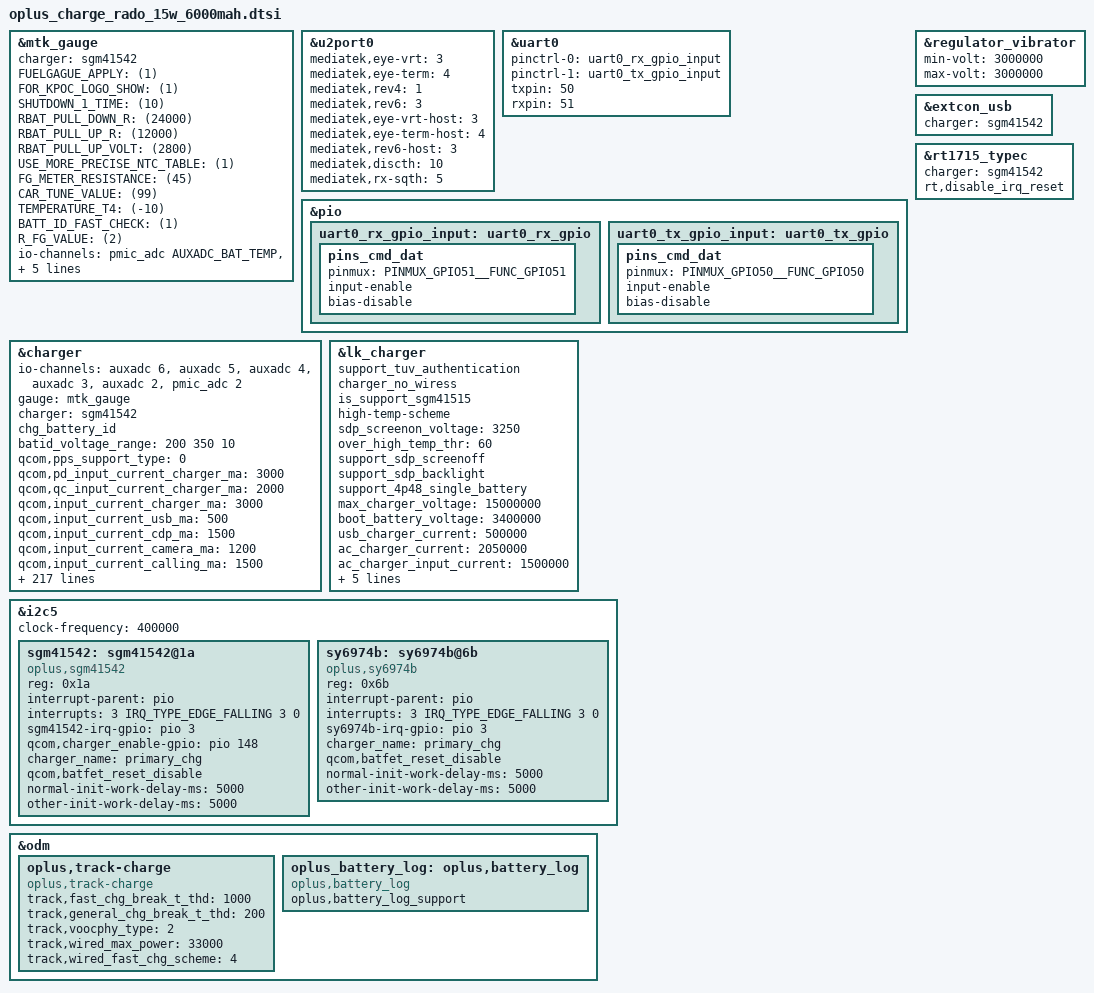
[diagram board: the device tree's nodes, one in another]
// SPDX-License-Identifier: GPL-2.0-only
/*
* Copyright (C) 2021-2020 Oplus. All rights reserved.
*/

/*
 *
 * CPU:MT6835 Barley
 * UTXD0 -->GPIO50
 * URXD0 -->GPIO51
 * I2C
 * MASTER_CHG/CCLOGIC --> I2C5
 * IRQB
 * EINT_CHG_1 (cp1 irq)                -->GPIO6
 * EINT_CHG_2 (cp2 irq)                -->GPIO18
 * CC_CNTL_INT_N(cc login irq)          --> GPIO12
 * CHG_INT(main irq)           --> GPIO3
 *
 * GPIO
 * MAIN/CCLOGIN_SCL               --> GPIO137(SCL5)
 * MAIN/CCLOGIN_SDA               --> GPIO138(SDA5)
 * USB_SWITCH_2(uart/vooc switch)      --> GPIO4
 * VBUS_SHORT(防烧口)           --> GPIO34
 * CHARGER_PUMP1_SCL               --> GPIO133(CP1_SCL3)
 * CHARGER_PUMP1_SDA               --> GPIO134(CP1_SDA3)
 * CHARGER_PUMP2_SCL               --> GPIO141(CP2_SCL7)
 * CHARGER_PUMP2_SDA               --> GPIO142(CP2_SDA7)
 * SEC_IC (加密电池GPIO for 67W)    --> GPIO44
 *
 * AP_AUXADC:
 * 0				--> FLASH_LED1_NTC
 * 1				--> NTC_USBCON_TEM (BTB VBUS旁)
 * 2				--> NTC_CHARGE (充电IC旁)
 * 3				--> USB_TEM2_ADC (BB_USB_ADC2 r/l?)
 * 4				--> USB_TEM1_ADC (BB_USB_ADC1)
 * 5				--> BAT_ID_ADC   (battery id)
 * 6				--> NTC_charging （BTB电池座子旁）
 */


#include <dt-bindings/iio/mt635x-auxadc.h>
#include <dt-bindings/pinctrl/mt6373-pinfunc.h>
#include <dt-bindings/pinctrl/mt65xx.h>
#include "oplus_chg.h"
/* charge start */

&mtk_gauge {
	status = "okay";
	charger = <&sgm41542>;
	FUELGAGUE_APPLY = <(1)>;
	FOR_KPOC_LOGO_SHOW = <(1)>;
	SHUTDOWN_1_TIME = <(10)>;
	RBAT_PULL_DOWN_R = <(24000)>;
	RBAT_PULL_UP_R = <(12000)>;
	RBAT_PULL_UP_VOLT = <(2800)>;
	USE_MORE_PRECISE_NTC_TABLE = <(1)>;
	//NTC_SERIES_R = <(5100)>;
	FG_METER_RESISTANCE = <(45)>; /* The resistance of PCB */
	CAR_TUNE_VALUE = <(99)>; /* Tune value for current measurement */
	TEMPERATURE_T4 = <(-10)>;
	BATT_ID_FAST_CHECK = <(1)>;
	R_FG_VALUE = <(2)>;/* R_sense resistance */
	io-channels = <&pmic_adc AUXADC_BAT_TEMP>,
				<&pmic_adc AUXADC_BATADC>,
				<&pmic_adc AUXADC_VBIF>,
				<&pmic_adc AUXADC_IMP>,
				<&pmic_adc AUXADC_IMIX_R>,
				<&auxadc 5>;
	io-channel-names = "pmic_battery_temp",
					"pmic_battery_voltage",
					"pmic_bif_voltage",
					"pmic_ptim_voltage",
					"pmic_ptim_r",
					 "auxadc5-batt_id_v";


    //IS_SUBBOARD_TEMP_SUPPORT = <(1)>;
	Enable_Is_Force_Full = <(1)>;
	DIM2_TABLE_DISTINGUISH = <(1)>;
	#include "mediatek/bat_setting/mt6835_rado_battery_table_15w_6000mah.dtsi"
	#include "mediatek/bat_setting/mt6835_rado_battery_prop_dim2_ext_15w_6000mah.dtsi"
};

&u2port0 {
    mediatek,eye-vrt = <3>;
    mediatek,eye-term = <4>;
    mediatek,rev4 = <1>;
    mediatek,rev6 = <3>;
    mediatek,eye-vrt-host = <3>;
    mediatek,eye-term-host = <4>;
    mediatek,rev6-host = <3>;
    mediatek,discth = <10>;
    mediatek,rx-sqth = <5>;
};

&uart0 {
	pinctrl-names = "uart0_rx_gpio", "uart0_tx_gpio";
	pinctrl-0 = <&uart0_rx_gpio_input>;
	pinctrl-1 = <&uart0_tx_gpio_input>;
	status = "okay";

	txpin = <50>;
	rxpin = <51>;
};

&pio {
	uart0_rx_gpio_input: uart0_rx_gpio {
		pins_cmd_dat {
			pinmux = <PINMUX_GPIO51__FUNC_GPIO51>;
			input-enable;
			bias-disable;
		};
	};

	uart0_tx_gpio_input: uart0_tx_gpio {
		pins_cmd_dat {
			pinmux = <PINMUX_GPIO50__FUNC_GPIO50>;
			input-enable;
			bias-disable;
		};
	};
};


&charger {
	io-channels = <&auxadc 6>,<&auxadc 5>,<&auxadc 4>,<&auxadc 3>,<&auxadc 2>,<&pmic_adc 2>;
	io-channel-names = "auxadc6_batt_btb_temp","auxadc5temp","usb_temp_v_l","usb_temp_v_r","auxadc2-chargeric_temp","pmic_vcdt_voltage";

	gauge = <&mtk_gauge>;
	charger = <&sgm41542>;

	chg_battery_id;
	batid_voltage_range = <200 350 10>;
	//for oplus chg framework:
	//qcom,pd_disable;
	qcom,pps_support_type = <0>;
	qcom,pd_input_current_charger_ma = <3000>;
	qcom,qc_input_current_charger_ma = <2000>;
	qcom,input_current_charger_ma = <3000>;
	qcom,input_current_usb_ma = <500>;
	qcom,input_current_cdp_ma = <1500>;
	qcom,input_current_camera_ma = <1200>;
	qcom,input_current_calling_ma = <1500>;

	qcom,led_warm_bat_decidegc = <350>;
	qcom,led_high_bat_decidegc = <370>;
	qcom,input_current_led_ma = <1200>;
	qcom,input_current_led_ma_high = <1200>;
	qcom,input_current_led_ma_warm = <1500>;
	qcom,input_current_led_ma_normal = <3000>;
	qcom,input_current_led_ma_forcmcc = <500>;
	qcom,input_current_led_ma_limit_high = <1200>;

	qcom,vooc_temp_bat_normal_decidegc = <350>;
	qcom,vooc_temp_bat_warm_decidegc = <370>;
	qcom,vooc_temp_bat_hot_decidegc = <440>;
	qcom,input_current_vooc_led_ma_high = <1200>;
	qcom,input_current_vooc_led_ma_warm = <1800>;
	qcom,input_current_vooc_led_ma_normal = <3600>;
	qcom,input_current_vooc_ma_normal = <3600>;
	qcom,input_current_vooc_ma_warm = <3200>;
	qcom,input_current_vooc_ma_high = <2200>;

	qcom,overtemp_bat_decidegc = <400>;
	qcom,iterm_disabled = <0>;
	//sw_full_count = <25>;
	qcom,iterm_ma = <303>;
	qcom,recharge-mv = <100>;

	qcom,batt_capacity_mah = <6000>; /*typical capacity*/
	qcom,usb_high_than_bat_decidegc = <168>;

	qcom,removed_bat_decidegc = <390>;  /* < -15C */

	qcom,cold_bat_decidegc = <100>;  /* -10C ~ 0C */
	qcom,temp_cold_vfloat_mv = <4490>;
	qcom,temp_cold_fastchg_current_ma_high = <879>;
	qcom,temp_cold_fastchg_current_ma_low = <879>;
	qcom,temp_cold_fastchg_current_ma = <879>;
	qcom,qc_temp_cold_fastchg_current_ma_high = <300>;
	qcom,qc_temp_cold_fastchg_current_ma_low = <300>;
	qcom,pd_temp_cold_fastchg_current_ma_high = <879>;
	qcom,pd_temp_cold_fastchg_current_ma_low = <879>;

	qcom,little_cold_bat_decidegc = <0>;    /* 0C ~ 5C */
	qcom,temp_little_cold_vfloat_mv = <4490>;
	qcom,temp_little_cold_fastchg_current_ma_high = <3000>;
	qcom,temp_little_cold_fastchg_current_ma_low = <2637>;
	qcom,temp_little_cold_fastchg_current_ma = <3000>;
	qcom,qc_temp_little_cold_fastchg_current_ma_high = <2200>;
	qcom,qc_temp_little_cold_fastchg_current_ma_low = <1250>;
	qcom,pd_temp_little_cold_fastchg_current_ma_high = <3000>;
	qcom,pd_temp_little_cold_fastchg_current_ma_low = <3000>;

	qcom,cool_bat_decidegc = <50>;  /* 5C ~ 12C */
	qcom,temp_cool_vfloat_mv = <4490>;
	qcom,temp_cool_fastchg_current_ma_high = <3000>;
	qcom,temp_cool_fastchg_current_ma_low = <3000>;
	qcom,qc_temp_cool_fastchg_current_ma_high = <2200>;
	qcom,qc_temp_cool_fastchg_current_ma_low = <2200>;
	qcom,pd_temp_cool_fastchg_current_ma_high = <3000>;
	qcom,pd_temp_cool_fastchg_current_ma_low = <3000>;

	qcom,little_cool_bat_decidegc = <120>;  /* 12C ~ 16C */
	qcom,temp_little_cool_vfloat_mv = <4490>;
	qcom,temp_little_cool_fastchg_current_ma_high = <3000>;
	qcom,temp_little_cool_fastchg_current_ma_low = <3000>;
	qcom,temp_little_cool_fastchg_current_ma = <3000>;
	qcom,pd_temp_little_cool_fastchg_current_ma_high = <3000>;
	qcom,pd_temp_little_cool_fastchg_current_ma_low = <3000>;
	qcom,pd_temp_little_cool_fastchg_current_ma = <3000>;
	qcom,qc_temp_little_cool_fastchg_current_ma_high = <2200>;
	qcom,qc_temp_little_cool_fastchg_current_ma_low = <2200>;
	qcom,qc_temp_little_cool_fastchg_current_ma = <2200>;

	qcom,normal_bat_decidegc = <160>;       /* 16C ~ 45C */
	qcom,temp_normal_vfloat_mv = <4470>;
	qcom,temp_normal_fastchg_current_ma = <3000>;
	qcom,temp_normal_fastchg_current_ma_high = <3000>;
	qcom,temp_normal_fastchg_current_ma_low = <3000>;
	qcom,pd_temp_normal_fastchg_current_ma = <3000>;
        qcom,pd_temp_normal_fastchg_current_ma_high = <3000>;
        qcom,pd_temp_normal_fastchg_current_ma_low = <3000>;

	qcom,qc_temp_normal_fastchg_current_ma = <2200>;

	qcom,warm_bat_decidegc = <450>;         /* 45C ~ 53C */ /*8pin Bat Vooc project need add 3 degree C*/
	qcom,temp_warm_vfloat_mv = <4130>;
	qcom,temp_warm_fastchg_current_ma = <3000>;
	qcom,pd_temp_warm_fastchg_current_ma = <3000>;
	qcom,qc_temp_warm_fastchg_current_ma = <1500>;
	qcom,temp_warm_fastchg_current_ma_led_on = <1000>;

	qcom,hot_bat_decidegc = <530>;  /* > 53C */

	qcom,non_standard_vfloat_mv = <3980>;
	qcom,non_standard_fastchg_current_ma = <512>;

	qcom,short_c_bat_cv_mv = <4330>;
	qcom,short_c_bat_vfloat_mv = <3800>;
	qcom,short_c_bat_fastchg_current_ma = <512>;
	qcom,short_c_bat_vfloat_sw_limit = <3750>;

	qcom,cold_vfloat_sw_limit = <4440>;
	qcom,little_cold_vfloat_sw_limit = <4440>;
	qcom,cool_vfloat_sw_limit = <4440>;
	qcom,little_cool_vfloat_sw_limit = <4440>;
	qcom,normal_vfloat_sw_limit = <4420>;
	qcom,warm_vfloat_sw_limit = <4080>;
	qcom,non_standard_vfloat_sw_limit = <3930>;

	qcom,max_chg_time_sec = <72000>;
	qcom,charger_hv_thr = <5850>;
	qcom,charger_recv_thr = <5850>;
	qcom,charger_lv_thr = <3400>;
	qcom,vbatt_full_thr = <4530>;
	qcom,vbatt_hv_thr = <4600>;

	qcom,vfloat_step_mv = <16>;
	qcom,non_standard_vfloat_over_sw_limit = <3990>;
	qcom,cold_vfloat_over_sw_limit = <4500>;
	qcom,little_cold_vfloat_over_sw_limit = <4500>;
	qcom,cool_vfloat_over_sw_limit = <4500>;
	qcom,little_cool_vfloat_over_sw_limit = <4500>;
	qcom,normal_vfloat_over_sw_limit = <4480>;
	qcom,warm_vfloat_over_sw_limit = <4140>;

	qcom,vbatt_power_off = <3300>;
	qcom,vbatt_soc_1 = <3410>;
	qcom,vooc_project = <0>;
	qcom,vbatt_num = <1>;
	qcom,new_ui_warning_support;
	qcom,smart_charging_screenoff;
	qcom,smart_charge_version = <1>;

	qcom,normal_vterm_hw_inc = <18>;
	qcom,non_normal_vterm_hw_inc = <18>;
	qcom,usbtemp_batttemp_gap = <12>;

	qcom,ff1_normal_fastchg_ma = <1500>; /*12C~35c*/
	qcom,ff1_warm_fastchg_ma = <1500>;	/* 35C ~ 40c */
	qcom,ff1_exit_step_ma = <650>;
	qcom,ff1_warm_exit_step_ma = <750>;

	qcom,ffc2_normal_fastchg_ma = <800>;/*12C~35c*/
	qcom,ffc2_warm_fastchg_ma = <900>;	/* 35C ~ 40c */
	qcom,ffc2_temp_warm_decidegc = <350>;
	qcom,ffc2_temp_high_decidegc = <400>;
	qcom,ffc2_temp_low_decidegc = <120>;
	qcom,ffc2_exit_step_ma = <650>;
	qcom,ffc2_warm_exit_step_ma = <750>;

	qcom,ffc_normal_vfloat_sw_limit = <4495>;
	qcom,ffc_temp_normal_vfloat_mv = <4550>;
	qcom,ffc_normal_vfloat_over_sw_limit = <4550>;
	qcom,ffc_warm_vfloat_sw_limit = <4495>;

	qcom,ffc2_normal_vfloat_sw_limit = <4495>;
	qcom,ffc2_temp_normal_vfloat_mv = <4550>;
	qcom,ffc2_normal_vfloat_over_sw_limit = <4550>;
	qcom,ffc2_warm_vfloat_sw_limit = <4495>;


	qcom,default_iterm_ma = <303>;
	qcom,default_temp_normal_fastchg_current_ma = <3000>;
	qcom,default_normal_vfloat_sw_limit = <4420>;
	qcom,default_temp_normal_vfloat_mv = <4470>;
	qcom,default_normal_vfloat_over_sw_limit = <4480>;

	qcom,default_temp_little_cool_fastchg_current_ma = <3000>;
	qcom,default_little_cool_vfloat_sw_limit = <4440>;
	qcom,default_temp_little_cool_vfloat_mv = <4490>;
	qcom,default_little_cool_vfloat_over_sw_limit = <4500>;

	//for PD9V or QC9V
	qcom,vbatt_pdqc_to_5v_thr = <4500>;
	qcom,vbatt_pdqc_to_9v_thr = <4500>;

	//for PD or QC control
	//qcom,pd_not_support = <1>;
	//qcom,qc_not_support = <1>;
	qcom,pd_support_5v3a = <1>;

	//for control:
	//qcom,suspend_after_full;
	qcom,support_abnormal_adapter;
	qcom,check_batt_full_by_sw;
	qcom,chg_ctrl_by_lcd;
	qcom,chg_ctrl_by_camera;
	qcom,chg_ctrl_by_calling;
	qcom,sw_vfloat_over_protect_enable;
	qcom,usbtemp_dischg_by_platpmic;
	//add for usb temp protect
	qcom,support_usbtemp_protect_v2;
	qcom,usbtemp_batt_temp_low = <50>;
	qcom,usbtemp_batt_temp_high = <50>;
	qcom,usbtemp_ntc_temp_low = <57>;
	qcom,usbtemp_ntc_temp_high = <69>;
	qcom,usbtemp_temp_gap_low_with_batt_temp = <7>;
	qcom,usbtemp_temp_gap_high_with_batt_temp = <12>;
	qcom,usbtemp_temp_gap_low_without_batt_temp = <12>;
	qcom,usbtemp_temp_gap_high_without_batt_temp = <24>;
	qcom.usbtemp_rise_fast_temp_low = <3>;
	qcom.usbtemp_rise_fast_temp_high = <3>;
	qcom.usbtemp_rise_fast_temp_count_low = <30>;
	qcom.usbtemp_rise_fast_temp_count_high = <20>;

	qcom,usbtemp_cool_down_ntc_low = <54>;
	qcom,usbtemp_cool_down_ntc_high = <65>;
	qcom,usbtemp_cool_down_gap_low = <12>;
	qcom,usbtemp_cool_down_gap_high = <20>;
	qcom,usbtemp_cool_down_recover_ntc_low = <48>;
	qcom,usbtemp_cool_down_recover_ntc_high = <60>;
	qcom,usbtemp_cool_down_recover_gap_low = <6>;
	qcom,usbtemp_cool_down_recover_gap_high = <15>;
	oplus,poweroff_high_batt_temp = <720>;
	oplus,poweroff_emergency_batt_temp = <770>;
	oplus,usbtemp_batt_temp_over_hot = <60>;
	oplus,usbtemp_temp_gap_with_batt_temp_in_over_hot = <15>;
	qcom,ffc_support;
	qcom,chargerid_vol_disable;
	qcom,support_ntc_01c_precision;
	qcom,voocphy_support = <0>;
	//qcom,external_authenticate;
	qcom,chargerid_support;
	qcom,vooc_show_ui_soc_decimal;
	qcom,ui_soc_decimal_speedmin = <20>;//2A
	//qcom,ccdetect_by_wd0;
	qcom,hvdcp_disabled; //do'not supprot hvdcp
	//GPIO config:
	//qcom,dischg-gpio = <&pio 34 0x00>;/*VBUS_SHORT*/

	qcom,vooc-max-input-volt-support = <10000>;     //10V
	qcom,vooc-max-input-current-support = <3000>;   //3A

	oplus,protocol_list = <CHG_PROTOCOL_BC12 15
				CHG_PROTOCOL_PD 15
				CHG_PROTOCOL_QC 10>;
	oplus,default_protocol_list = <CHG_PROTOCOL_BC12
					CHG_PROTOCOL_PD>;
	oplus,uart_tx-gpio = <&pio 50 0x00>;
	oplus,uart_rx-gpio = <&pio 51 0x00>;
};

&lk_charger {
	support_tuv_authentication;
	charger_no_wiress;
	is_support_sgm41515;
	high-temp-scheme;
	sdp_screenon_voltage = <3250>;
	//sub_board_temp_support;
	over_high_temp_thr = <60>;
	support_sdp_screenoff;
	support_sdp_backlight;
	support_4p48_single_battery;
	max_charger_voltage = <15000000>;
	boot_battery_voltage = <3400000>;
	usb_charger_current = <500000>;
	ac_charger_current = <2050000>;
	ac_charger_input_current = <1500000>;
	non_std_ac_charger_current = <750000>;
	charging_host_charger_current = <1500000>;
	ta_ac_charger_current = <1500000>;
	pd_charger_current = <500000>;
	is_support_second_charge_ic;
};

&i2c5 {
	status = "okay";
	clock-frequency = <400000>;//400K
	sgm41542:sgm41542@1a {
		status = "okay";
		compatible = "oplus,sgm41542";
		reg = <0x1a>;

		interrupt-parent = <&pio>;
		interrupts = <3 IRQ_TYPE_EDGE_FALLING 3 0>;
		sgm41542-irq-gpio = <&pio 3 0x00>;
		qcom,charger_enable-gpio = <&pio 148 0x00>;
		/*pinctrl-names = "default";
		pinctrl-0 = <&sgm41542_int_default>;*/
		/*
		* Charger name
		* Main charger: primary_chg
		* Slave charger: secondary_chg
		*/
		charger_name = "primary_chg";
		qcom,batfet_reset_disable;      /*1:disable 0:enable*/
		normal-init-work-delay-ms = <5000>;
		other-init-work-delay-ms = <5000>;
	};

	sy6974b:sy6974b@6b {
		status = "okay";
		compatible = "oplus,sy6974b";
		reg = <0x6b>;

		interrupt-parent = <&pio>;
		interrupts = <3 IRQ_TYPE_EDGE_FALLING 3 0>;
		sy6974b-irq-gpio = <&pio 3 0x00>;
		/*pinctrl-names = "default";
		pinctrl-0 = <&sy6974b_int_default>;*/
		/*
		* Charger name
		* Main charger: primary_chg
		* Slave charger: secondary_chg
		*/
		charger_name = "primary_chg";
		qcom,batfet_reset_disable;      /*1:disable 0:enable*/
		normal-init-work-delay-ms = <5000>;
		other-init-work-delay-ms = <5000>;
	};
};

/*
&i2c9 {
    status = "okay";
    clock-frequency = <400000>;

    bq27541-battery@55 {
        status = "okay";
        compatible = "oplus,bq27541-battery";
        reg = <0x55>;
    };
};
*/

&regulator_vibrator{
	min-volt = <3000000>;
	max-volt = <3000000>;
};

&extcon_usb {
	charger = <&sgm41542>;
	status = "okay";
};

&charger {
	charger = <&sgm41542>;
	status = "okay";
};

#include "mediatek/tcpc_rt1715.dtsi"
&rt1715_typec {
	charger = <&sgm41542>;
	status = "okay";
	rt,disable_irq_reset;
};

/*&sgm7220_typec {
	charger = <&sgm41542>;
	status = "okay";
};*/

&odm {
	oplus,track-charge {
		compatible = "oplus,track-charge";
		track,fast_chg_break_t_thd = <1000>;
		track,general_chg_break_t_thd = <200>;
		track,voocphy_type = <2>;
		track,wired_max_power = <33000>;
		track,wired_fast_chg_scheme = <4>;
	};

	oplus_battery_log: oplus,battery_log {
		compatible = "oplus,battery_log";
		oplus,battery_log_support;
	};
};

#include "mediatek/oplus_charge_rado_15w_6000mah_sy6974b.dtsi"
/* chagrge end */
